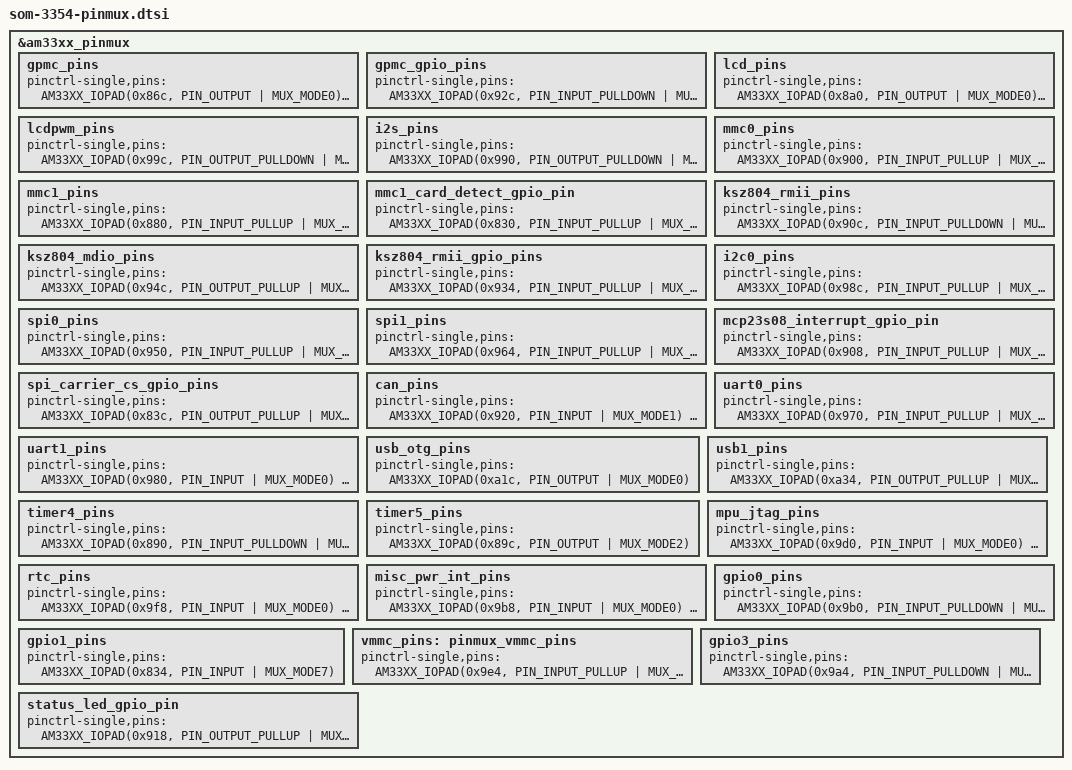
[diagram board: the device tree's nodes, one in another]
/* This file was auto-generated by TI PinMux on 11/16/2021 at 6:20:11 PM. */
/* This file should only be used as a reference. Some pins/peripherals, */
/* depending on your use case, may need additional configuration. */

/* Some or all the pins from the following groups are not used by device tree 
adc
ddr
misc_pwr_int
26mhzosc
32khzosc
usb_otg
usb1
*/

&am33xx_pinmux {
	gpmc_pins: gpmc_pins {
		pinctrl-single,pins = <
			AM33XX_IOPAD(0x86c, PIN_OUTPUT | MUX_MODE0) /* (V17) gpmc_a11.gpmc_a11 */
			AM33XX_IOPAD(0x868, PIN_OUTPUT | MUX_MODE0) /* (T16) gpmc_a10.gpmc_a10 */
			AM33XX_IOPAD(0x864, PIN_OUTPUT | MUX_MODE0) /* (U16) gpmc_a9.gpmc_a9 */
			AM33XX_IOPAD(0x860, PIN_OUTPUT | MUX_MODE0) /* (V16) gpmc_a8.gpmc_a8 */
			AM33XX_IOPAD(0x85c, PIN_OUTPUT | MUX_MODE0) /* (T15) gpmc_a7.gpmc_a7 */
			AM33XX_IOPAD(0x858, PIN_OUTPUT | MUX_MODE0) /* (U15) gpmc_a6.gpmc_a6 */
			AM33XX_IOPAD(0x854, PIN_OUTPUT | MUX_MODE0) /* (V15) gpmc_a5.gpmc_a5 */
			AM33XX_IOPAD(0x850, PIN_OUTPUT | MUX_MODE0) /* (R14) gpmc_a4.gpmc_a4 */
			AM33XX_IOPAD(0x84c, PIN_OUTPUT | MUX_MODE0) /* (T14) gpmc_a3.gpmc_a3 */
			AM33XX_IOPAD(0x848, PIN_OUTPUT | MUX_MODE0) /* (U14) gpmc_a2.gpmc_a2 */
			AM33XX_IOPAD(0x844, PIN_OUTPUT | MUX_MODE0) /* (V14) gpmc_a1.gpmc_a1 */
			AM33XX_IOPAD(0x840, PIN_OUTPUT | MUX_MODE0) /* (R13) gpmc_a0.gpmc_a0 */
			AM33XX_IOPAD(0x81c, PIN_INPUT_PULLUP | MUX_MODE0) /* (T9) gpmc_ad7.gpmc_ad7 */
			AM33XX_IOPAD(0x818, PIN_INPUT_PULLUP | MUX_MODE0) /* (R9) gpmc_ad6.gpmc_ad6 */
			AM33XX_IOPAD(0x814, PIN_INPUT_PULLUP | MUX_MODE0) /* (V8) gpmc_ad5.gpmc_ad5 */
			AM33XX_IOPAD(0x810, PIN_INPUT_PULLUP | MUX_MODE0) /* (U8) gpmc_ad4.gpmc_ad4 */
			AM33XX_IOPAD(0x80c, PIN_INPUT_PULLUP | MUX_MODE0) /* (T8) gpmc_ad3.gpmc_ad3 */
			AM33XX_IOPAD(0x808, PIN_INPUT_PULLUP | MUX_MODE0) /* (R8) gpmc_ad2.gpmc_ad2 */
			AM33XX_IOPAD(0x804, PIN_INPUT_PULLUP | MUX_MODE0) /* (V7) gpmc_ad1.gpmc_ad1 */
			AM33XX_IOPAD(0x800, PIN_INPUT_PULLUP | MUX_MODE0) /* (U7) gpmc_ad0.gpmc_ad0 */
			AM33XX_IOPAD(0x88c, PIN_INPUT | MUX_MODE2) /* (V12) gpmc_clk.gpmc_wait1 */
			AM33XX_IOPAD(0x87c, PIN_OUTPUT | MUX_MODE0) /* (V6) gpmc_csn0.gpmc_csn0 */
			AM33XX_IOPAD(0x888, PIN_OUTPUT | MUX_MODE0) /* (T13) gpmc_csn3.gpmc_csn3 */
			AM33XX_IOPAD(0x870, PIN_OUTPUT | MUX_MODE2) /* (T17) gpmc_wait0.gpmc_csn4 */
			AM33XX_IOPAD(0x874, PIN_OUTPUT | MUX_MODE2) /* (U17) gpmc_wpn.gpmc_csn5 */
			AM33XX_IOPAD(0x878, PIN_OUTPUT | MUX_MODE2) /* (U18) gpmc_be1n.gpmc_csn6 */
			AM33XX_IOPAD(0x894, PIN_OUTPUT | MUX_MODE0) /* (T7) gpmc_oen_ren.gpmc_oen_ren */
			AM33XX_IOPAD(0x898, PIN_OUTPUT | MUX_MODE0) /* (U6) gpmc_wen.gpmc_wen */
		>;
	};

	gpmc_gpio_pins: gpmc_gpio_pins {
		pinctrl-single,pins = <
			AM33XX_IOPAD(0x92c, PIN_INPUT_PULLDOWN | MUX_MODE7) /* (K18) gmii1_txclk.gpio3[9] */
			AM33XX_IOPAD(0x930, PIN_INPUT_PULLDOWN | MUX_MODE7) /* (L18) gmii1_rxclk.gpio3[10] */
		>;
	};

	lcd_pins: lcd_pins {
		pinctrl-single,pins = <
			AM33XX_IOPAD(0x8a0, PIN_OUTPUT | MUX_MODE0) /* (R1) lcd_data0.lcd_data0 */
			AM33XX_IOPAD(0x8a4, PIN_OUTPUT | MUX_MODE0) /* (R2) lcd_data1.lcd_data1 */
			AM33XX_IOPAD(0x8a8, PIN_OUTPUT | MUX_MODE0) /* (R3) lcd_data2.lcd_data2 */
			AM33XX_IOPAD(0x8ac, PIN_OUTPUT | MUX_MODE0) /* (R4) lcd_data3.lcd_data3 */
			AM33XX_IOPAD(0x8b0, PIN_OUTPUT | MUX_MODE0) /* (T1) lcd_data4.lcd_data4 */
			AM33XX_IOPAD(0x8b4, PIN_OUTPUT | MUX_MODE0) /* (T2) lcd_data5.lcd_data5 */
			AM33XX_IOPAD(0x8b8, PIN_OUTPUT | MUX_MODE0) /* (T3) lcd_data6.lcd_data6 */
			AM33XX_IOPAD(0x8bc, PIN_OUTPUT | MUX_MODE0) /* (T4) lcd_data7.lcd_data7 */
			AM33XX_IOPAD(0x8c0, PIN_OUTPUT | MUX_MODE0) /* (U1) lcd_data8.lcd_data8 */
			AM33XX_IOPAD(0x8c4, PIN_OUTPUT | MUX_MODE0) /* (U2) lcd_data9.lcd_data9 */
			AM33XX_IOPAD(0x8c8, PIN_OUTPUT | MUX_MODE0) /* (U3) lcd_data10.lcd_data10 */
			AM33XX_IOPAD(0x8cc, PIN_OUTPUT | MUX_MODE0) /* (U4) lcd_data11.lcd_data11 */
			AM33XX_IOPAD(0x8d0, PIN_OUTPUT | MUX_MODE0) /* (V2) lcd_data12.lcd_data12 */
			AM33XX_IOPAD(0x8d4, PIN_OUTPUT | MUX_MODE0) /* (V3) lcd_data13.lcd_data13 */
			AM33XX_IOPAD(0x8d8, PIN_OUTPUT | MUX_MODE0) /* (V4) lcd_data14.lcd_data14 */
			AM33XX_IOPAD(0x8dc, PIN_OUTPUT | MUX_MODE0) /* (T5) lcd_data15.lcd_data15 */
			AM33XX_IOPAD(0x8e0, PIN_OUTPUT_PULLDOWN | MUX_MODE0) /* (U5) lcd_vsync.lcd_vsync */
			AM33XX_IOPAD(0x8e4, PIN_OUTPUT_PULLDOWN | MUX_MODE0) /* (R5) lcd_hsync.lcd_hsync */
			AM33XX_IOPAD(0x8e8, PIN_OUTPUT_PULLDOWN | MUX_MODE0) /* (V5) lcd_pclk.lcd_pclk */
			AM33XX_IOPAD(0x8ec, PIN_OUTPUT_PULLDOWN | MUX_MODE0) /* (R6) lcd_ac_bias_en.lcd_ac_bias_en */
		>;
	};

	lcdpwm_pins: lcdpwm_pins {
		pinctrl-single,pins = <
			AM33XX_IOPAD(0x99c, PIN_OUTPUT_PULLDOWN | MUX_MODE4) /* (C12) mcasp0_ahclkr.eCAP2_in_PWM2_out */
		>;
	};

	i2s_pins: i2s_pins {
		pinctrl-single,pins = <
			AM33XX_IOPAD(0x990, PIN_OUTPUT_PULLDOWN | MUX_MODE0) /* (A13) mcasp0_aclkx.mcasp0_aclkx */
			AM33XX_IOPAD(0x994, PIN_OUTPUT_PULLDOWN | MUX_MODE0) /* (B13) mcasp0_fsx.mcasp0_fsx */
			AM33XX_IOPAD(0x998, PIN_OUTPUT_PULLDOWN | MUX_MODE0) /* (D12) mcasp0_axr0.mcasp0_axr0 */
			AM33XX_IOPAD(0x9a8, PIN_OUTPUT_PULLDOWN | MUX_MODE0) /* (D13) mcasp0_axr1.mcasp0_axr1 */
		>;
	};

	mmc0_pins: mmc0_pins {
		pinctrl-single,pins = <
			AM33XX_IOPAD(0x900, PIN_INPUT_PULLUP | MUX_MODE0) /* (G17) mmc0_clk.mmc0_clk */
			AM33XX_IOPAD(0x904, PIN_INPUT_PULLUP | MUX_MODE0) /* (G18) mmc0_cmd.mmc0_cmd */
			AM33XX_IOPAD(0x8fc, PIN_INPUT_PULLUP | MUX_MODE0) /* (G16) mmc0_dat0.mmc0_dat0 */
			AM33XX_IOPAD(0x8f8, PIN_INPUT_PULLUP | MUX_MODE0) /* (G15) mmc0_dat1.mmc0_dat1 */
			AM33XX_IOPAD(0x8f4, PIN_INPUT_PULLUP | MUX_MODE0) /* (F18) mmc0_dat2.mmc0_dat2 */
			AM33XX_IOPAD(0x8f0, PIN_INPUT_PULLUP | MUX_MODE0) /* (F17) mmc0_dat3.mmc0_dat3 */
		>;
	};

	mmc1_pins: mmc1_pins {
		pinctrl-single,pins = <
			AM33XX_IOPAD(0x880, PIN_INPUT_PULLUP | MUX_MODE2) /* (U9) gpmc_csn1.mmc1_clk */
			AM33XX_IOPAD(0x884, PIN_INPUT_PULLUP | MUX_MODE2) /* (V9) gpmc_csn2.mmc1_cmd */
			AM33XX_IOPAD(0x820, PIN_INPUT_PULLUP | MUX_MODE2) /* (U10) gpmc_ad8.mmc1_dat0 */
			AM33XX_IOPAD(0x824, PIN_INPUT_PULLUP | MUX_MODE2) /* (T10) gpmc_ad9.mmc1_dat1 */
			AM33XX_IOPAD(0x828, PIN_INPUT_PULLUP | MUX_MODE2) /* (T11) gpmc_ad10.mmc1_dat2 */
			AM33XX_IOPAD(0x82c, PIN_INPUT_PULLUP | MUX_MODE2) /* (U12) gpmc_ad11.mmc1_dat3 */
		>;
	};

	mmc1_card_detect_gpio_pin: mmc1_card_detect_gpio_pin {
		pinctrl-single,pins = <
			AM33XX_IOPAD(0x830, PIN_INPUT_PULLUP | MUX_MODE7) /* (T12) gpmc_ad12.gpio1[12] */
		>;
	};

	ksz804_rmii_pins: ksz804_rmii_pins {
		pinctrl-single,pins = <
			AM33XX_IOPAD(0x90c, PIN_INPUT_PULLDOWN | MUX_MODE1) /* (H17) gmii1_crs.rmii1_crs_dv */
			AM33XX_IOPAD(0x910, PIN_INPUT_PULLUP | MUX_MODE1) /* (J15) gmii1_rxer.rmii1_rxer */
			AM33XX_IOPAD(0x914, PIN_OUTPUT_PULLDOWN | MUX_MODE1) /* (J16) gmii1_txen.rmii1_txen */
			AM33XX_IOPAD(0x928, PIN_OUTPUT_PULLDOWN | MUX_MODE1) /* (K17) gmii1_txd0.rmii1_txd0 */
			AM33XX_IOPAD(0x924, PIN_OUTPUT_PULLDOWN | MUX_MODE1) /* (K16) gmii1_txd1.rmii1_txd1 */
			AM33XX_IOPAD(0x940, PIN_INPUT_PULLDOWN | MUX_MODE1) /* (M16) gmii1_rxd0.rmii1_rxd0 */
			AM33XX_IOPAD(0x93c, PIN_INPUT_PULLDOWN | MUX_MODE1) /* (L15) gmii1_rxd1.rmii1_rxd1 */
			AM33XX_IOPAD(0x944, PIN_INPUT_PULLDOWN | MUX_MODE0) /* (H18) rmii1_refclk.rmii1_refclk */
		>;
	};

	ksz804_mdio_pins: ksz804_mdio_pins {
		pinctrl-single,pins = <
			AM33XX_IOPAD(0x94c, PIN_OUTPUT_PULLUP | MUX_MODE0) /* (M18) mdio_clk.mdio_clk */
			AM33XX_IOPAD(0x948, PIN_INPUT_PULLUP | MUX_MODE0) /* (M17) mdio_data.mdio_data */
		>;
	};

	ksz804_rmii_gpio_pins: ksz804_rmii_gpio_pins {
		pinctrl-single,pins = <
			AM33XX_IOPAD(0x934, PIN_INPUT_PULLUP | MUX_MODE7) /* (L17) gmii1_rxd3.gpio2[18] */
			AM33XX_IOPAD(0x938, PIN_OUTPUT_PULLUP | MUX_MODE7) /* (L16) gmii1_rxd2.gpio2[19] */
		>;
	};

	i2c0_pins: i2c0_pins {
		pinctrl-single,pins = <
			AM33XX_IOPAD(0x98c, PIN_INPUT_PULLUP | MUX_MODE0) /* (C16) I2C0_SCL.I2C0_SCL */
			AM33XX_IOPAD(0x988, PIN_INPUT_PULLUP | MUX_MODE0) /* (C17) I2C0_SDA.I2C0_SDA */
		>;
	};

	spi0_pins: spi0_pins {
		pinctrl-single,pins = <
			AM33XX_IOPAD(0x950, PIN_INPUT_PULLUP | MUX_MODE0) /* (A17) spi0_sclk.spi0_sclk */
			AM33XX_IOPAD(0x954, PIN_INPUT_PULLUP | MUX_MODE0) /* (B17) spi0_d0.spi0_d0 */
			AM33XX_IOPAD(0x958, PIN_INPUT_PULLUP | MUX_MODE0) /* (B16) spi0_d1.spi0_d1 */
			AM33XX_IOPAD(0x95c, PIN_OUTPUT_PULLUP | MUX_MODE0) /* SPI FLASH CS (A16) spi0_cs0.spi0_cs0 */
			AM33XX_IOPAD(0x960, PIN_OUTPUT_PULLUP | MUX_MODE0) /* SPI MCP23S08 CS (C15) spi0_cs1.spi0_cs1 */
		>;
	};

	spi1_pins: spi1_pins {
		pinctrl-single,pins = <
			AM33XX_IOPAD(0x964, PIN_INPUT_PULLUP | MUX_MODE4) /* (C18) eCAP0_in_PWM0_out.spi1_sclk */
			AM33XX_IOPAD(0x968, PIN_INPUT_PULLUP | MUX_MODE4) /* (E18) uart0_ctsn.spi1_d0 */
			AM33XX_IOPAD(0x96c, PIN_INPUT_PULLUP | MUX_MODE4) /* (E17) uart0_rtsn.spi1_d1 */
		>;
	};

	mcp23s08_interrupt_gpio_pin: mcp23s08_interrupt_gpio_pin {
		pinctrl-single,pins = <
			AM33XX_IOPAD(0x908, PIN_INPUT_PULLUP | MUX_MODE7) /* (H16) gmii1_col.gpio3[0] */
		>;
	};

	spi_carrier_cs_gpio_pins: spi_carrier_cs_gpio_pins {
		pinctrl-single,pins = <
			AM33XX_IOPAD(0x83c, PIN_OUTPUT_PULLUP | MUX_MODE7) /* SPI_CS0 (U13) gpmc_ad15.gpio1[15] */
			AM33XX_IOPAD(0x838, PIN_OUTPUT_PULLUP | MUX_MODE7) /* SPI_CS1 (V13) gpmc_ad14.gpio1[14] */
			AM33XX_IOPAD(0x9e8, PIN_OUTPUT_PULLUP | MUX_MODE7) /* SPI_CS2 (B14) EMU1.gpio3[8] */
			AM33XX_IOPAD(0x9a0, PIN_OUTPUT_PULLUP | MUX_MODE7) /* SPI_CS3 (B12) mcasp0_aclkr.gpio3[18] */
		>;
	};
	
	can_pins: can_pins {
		pinctrl-single,pins = <
			AM33XX_IOPAD(0x920, PIN_INPUT | MUX_MODE1) /* (K15) gmii1_txd2.dcan0_rx */
			AM33XX_IOPAD(0x91c, PIN_OUTPUT | MUX_MODE1) /* (J18) gmii1_txd3.dcan0_tx */
		>;
	};

	uart0_pins: uart0_pins {
		pinctrl-single,pins = <
			AM33XX_IOPAD(0x970, PIN_INPUT_PULLUP | MUX_MODE0) /* (E15) uart0_rxd.uart0_rxd */
			AM33XX_IOPAD(0x974, PIN_OUTPUT_PULLDOWN | MUX_MODE0) /* (E16) uart0_txd.uart0_txd */
		>;
	};

	uart1_pins: uart1_pins {
		pinctrl-single,pins = <
			AM33XX_IOPAD(0x980, PIN_INPUT | MUX_MODE0) /* (D16) uart1_rxd.uart1_rxd */
			AM33XX_IOPAD(0x984, PIN_OUTPUT | MUX_MODE0) /* (D15) uart1_txd.uart1_txd */
			AM33XX_IOPAD(0x978, PIN_INPUT | MUX_MODE0) /* (D18) uart1_ctsn.uart1_ctsn */
			AM33XX_IOPAD(0x97c, PIN_OUTPUT | MUX_MODE0) /* (D17) uart1_rtsn.uart1_rtsn */
		>;
	};

	usb_otg_pins: usb_otg_pins {
		pinctrl-single,pins = <
			AM33XX_IOPAD(0xa1c, PIN_OUTPUT | MUX_MODE0) /* (F16) USB0_DRVVBUS.USB0_DRVVBUS */
		>;
	};

	usb1_pins: usb1_pins {
		pinctrl-single,pins = <
			AM33XX_IOPAD(0xa34, PIN_OUTPUT_PULLUP | MUX_MODE0) /* (F15) USB1_DRVVBUS.USB1_DRVVBUS */
		>;
	};
	
	timer4_pins: timer4_pins {
		pinctrl-single,pins = <
			AM33XX_IOPAD(0x890, PIN_INPUT_PULLDOWN | MUX_MODE2) /* GPIO14 (R7) gpmc_advn_ale.timer4 */
		>;
	};

	timer5_pins: timer5_pins {
		pinctrl-single,pins = <
			AM33XX_IOPAD(0x89c, PIN_OUTPUT | MUX_MODE2) /* OSC1 (T6) gpmc_be0n_cle.timer5 */
		>;
	};
	
	mpu_jtag_pins: mpu_jtag_pins {
		pinctrl-single,pins = <
			AM33XX_IOPAD(0x9d0, PIN_INPUT | MUX_MODE0) /* (C11) TMS.TMS */
			AM33XX_IOPAD(0x9d4, PIN_INPUT | MUX_MODE0) /* (B11) TDI.TDI */
			AM33XX_IOPAD(0x9d8, PIN_OUTPUT | MUX_MODE0) /* (A11) TDO.TDO */
			AM33XX_IOPAD(0x9dc, PIN_INPUT | MUX_MODE0) /* (A12) TCK.TCK */
			AM33XX_IOPAD(0x9e0, PIN_INPUT | MUX_MODE0) /* (B10) nTRST.nTRST */
		>;
	};

	rtc_pins: rtc_pins {
		pinctrl-single,pins = <
			AM33XX_IOPAD(0x9f8, PIN_INPUT | MUX_MODE0) /* (B5) RTC_PORz.RTC_PORz */
			AM33XX_IOPAD(0xa00, PIN_OUTPUT | MUX_MODE0) /* (C5) EXT_WAKEUP.EXT_WAKEUP */
			AM33XX_IOPAD(0x9fc, PIN_INPUT | MUX_MODE0) /* (C6) PMIC_POWER_EN.PMIC_POWER_EN */
			AM33XX_IOPAD(0xa04, PIN_INPUT | MUX_MODE0) /* (B4) ENZ_KALDO_1P8V.ENZ_KALDO_1P8V */
		>;
	};
	
	misc_pwr_int_pins: misc_pwr_int_pins {
		pinctrl-single,pins = <
			AM33XX_IOPAD(0x9b8, PIN_INPUT | MUX_MODE0) /* (A10) nRESETIN_OUT.nRESETIN_OUT */
			AM33XX_IOPAD(0x9c0, PIN_INPUT | MUX_MODE0) /* (B18) nNMI.nNMI */
		>;
	};

	gpio0_pins: gpio0_pins {
		pinctrl-single,pins = <
			AM33XX_IOPAD(0x9b0, PIN_INPUT_PULLDOWN | MUX_MODE7) /* IRQA (A15) xdma_event_intr0.gpio0[19] */
			AM33XX_IOPAD(0x9b4, PIN_OUTPUT_PULLDOWN | MUX_MODE7) /* GPIO15 (D14) xdma_event_intr1.gpio0[20] */
		>;
	};

	gpio1_pins: gpio1_pins {
		pinctrl-single,pins = <
			AM33XX_IOPAD(0x834, PIN_INPUT | MUX_MODE7) /* GPIO0 (R12) gpmc_ad13.gpio1[13] */
		>;
	};

	vmmc_pins: pinmux_vmmc_pins {
		pinctrl-single,pins = <
			AM33XX_IOPAD(0x9e4, PIN_INPUT_PULLUP | MUX_MODE7)		/* emu0.gpio3_7 */
		>;
	};

	gpio3_pins: gpio3_pins {
		pinctrl-single,pins = <
			AM33XX_IOPAD(0x9a4, PIN_INPUT_PULLDOWN | MUX_MODE7) /* IRQB (C13) mcasp0_fsr.gpio3[19] */
			AM33XX_IOPAD(0x9ac, PIN_INPUT_PULLDOWN | MUX_MODE7) /* IRQC (A14) mcasp0_ahclkx.gpio3[21] */
		>;
	};

	status_led_gpio_pin: status_led_gpio_pin {
		pinctrl-single,pins = <
			AM33XX_IOPAD(0x918, PIN_OUTPUT_PULLUP | MUX_MODE7) /* (J17) gmii1_rxdv.gpio3[4] */
		>;
	};
};
